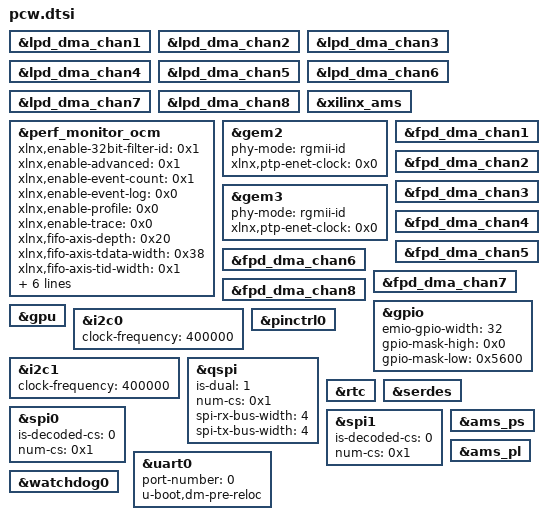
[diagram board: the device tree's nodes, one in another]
/*
 * CAUTION: This file is automatically generated by Xilinx.
 * Version:  
 * Today is: Fri Jul  6 09:09:26 2018
 */


&lpd_dma_chan1 {
	status = "okay";
};
&lpd_dma_chan2 {
	status = "okay";
};
&lpd_dma_chan3 {
	status = "okay";
};
&lpd_dma_chan4 {
	status = "okay";
};
&lpd_dma_chan5 {
	status = "okay";
};
&lpd_dma_chan6 {
	status = "okay";
};
&lpd_dma_chan7 {
	status = "okay";
};
&lpd_dma_chan8 {
	status = "okay";
};
&xilinx_ams {
	status = "okay";
};
&perf_monitor_ocm {
	xlnx,enable-32bit-filter-id = <0x1>;
	xlnx,enable-advanced = <0x1>;
	xlnx,enable-event-count = <0x1>;
	xlnx,enable-event-log = <0x0>;
	xlnx,enable-profile = <0x0>;
	xlnx,enable-trace = <0x0>;
	xlnx,fifo-axis-depth = <0x20>;
	xlnx,fifo-axis-tdata-width = <0x38>;
	xlnx,fifo-axis-tid-width = <0x1>;
	xlnx,global-count-width = <0x20>;
	xlnx,have-sampled-metric-cnt = <0x1>;
	xlnx,metric-count-scale = <0x1>;
	xlnx,metrics-sample-count-width = <0x20>;
	xlnx,num-monitor-slots = <0x1>;
	xlnx,num-of-counters = <0x3>;
};
&gem2 {
	phy-mode = "rgmii-id";
	status = "okay";
	xlnx,ptp-enet-clock = <0x0>;
};
&gem3 {
	phy-mode = "rgmii-id";
	status = "okay";
	xlnx,ptp-enet-clock = <0x0>;
};
&fpd_dma_chan1 {
	status = "okay";
};
&fpd_dma_chan2 {
	status = "okay";
};
&fpd_dma_chan3 {
	status = "okay";
};
&fpd_dma_chan4 {
	status = "okay";
};
&fpd_dma_chan5 {
	status = "okay";
};
&fpd_dma_chan6 {
	status = "okay";
};
&fpd_dma_chan7 {
	status = "okay";
};
&fpd_dma_chan8 {
	status = "okay";
};
&gpio {
	emio-gpio-width = <32>;
	gpio-mask-high = <0x0>;
	gpio-mask-low = <0x5600>;
	status = "okay";
};
&gpu {
	status = "okay";
};
&i2c0 {
	clock-frequency = <400000>;
	status = "okay";
};
&i2c1 {
	clock-frequency = <400000>;
	status = "okay";
};
&pinctrl0 {
	status = "okay";
};
&qspi {
	is-dual = <1>;
	num-cs = <0x1>;
	spi-rx-bus-width = <4>;
	spi-tx-bus-width = <4>;
	status = "okay";
};
&rtc {
	status = "okay";
};
&serdes {
	status = "okay";
};
&spi0 {
	is-decoded-cs = <0>;
	num-cs = <0x1>;
	status = "okay";
};
&spi1 {
	is-decoded-cs = <0>;
	num-cs = <0x1>;
	status = "okay";
};
&uart0 {
	device_type = "serial";
	port-number = <0>;
	status = "okay";
	u-boot,dm-pre-reloc ;
};
&watchdog0 {
	status = "okay";
};
&ams_ps {
	status = "okay";
};
&ams_pl {
	status = "okay";
};
